# RX64M_RSPI_Pilot register map
File version: 1.0
RX64M_RSPI_Pilot peripheral registers generated from iodefine.h (pilot).
Registers are 8-bit, read-write, reset 0x0 unless marked. A register's access mark holds for its fields unless they carry their own. Offsets are from the block's base; lines under a group give offsets from that group; [hi:lo] are bit positions; {n}, {i} and the like mark numbered series; 'fields as' and 'values as' point back to an identical list; <NAME> marks a mode.

## Memory map
0x000D0100 RSPI0 size 0x20

## RSPI0
Base 0x000D0100
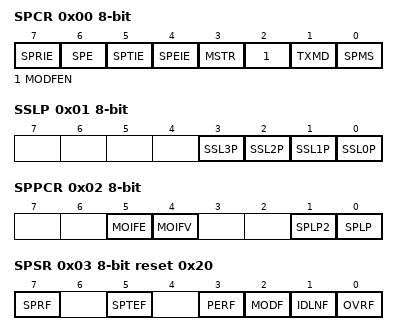
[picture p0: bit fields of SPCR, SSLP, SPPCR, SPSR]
0x00 SPCR
  [7] SPRIE, [6] SPE, [5] SPTIE, [4] SPEIE, [3] MSTR, [2] MODFEN, [1] TXMD, [0] SPMS
0x01 SSLP
  [n] SSL{n}P (n=0..3)
0x02 SPPCR
  [5] MOIFE, [4] MOIFV, [1] SPLP2, [0] SPLP
0x03 SPSR reset 0x20
  [7] SPRF, [5] SPTEF, [3] PERF, [2] MODF, [1] IDLNF, [0] OVRF
0x04 SPDR 32-bit
0x08 SPSCR
  [2:0] SPSLN
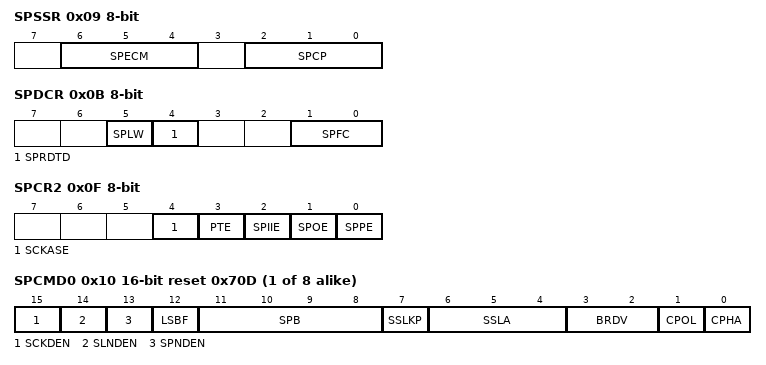
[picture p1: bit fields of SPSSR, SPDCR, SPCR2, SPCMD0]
0x09 SPSSR ro
  [6:4] SPECM, [2:0] SPCP
0x0A SPBR reset 0xFF
0x0B SPDCR
  [5] SPLW, [4] SPRDTD, [1:0] SPFC
0x0C SPCKD
  [2:0] SCKDL
0x0D SSLND
  [2:0] SLNDL
0x0E SPND
  [2:0] SPNDL
0x0F SPCR2
  [4] SCKASE, [3] PTE, [2] SPIIE, [1] SPOE, [0] SPPE
{0x10+2i} SPCMD{i} 16-bit reset 0x70D (i=0..7)
  [15] SCKDEN, [14] SLNDEN, [13] SPNDEN, [12] LSBF, [11:8] SPB, [7] SSLKP, [6:4] SSLA, [3:2] BRDV, [1] CPOL, [0] CPHA
